# STM32WB30CEU6A register map
File version: 1.0
Registers are 32-bit, access not given, reset 0x0 unless marked. A register's access mark holds for its fields unless they carry their own. Offsets are from the block's base; [hi:lo] are bit positions; {n}, {i} and the like mark numbered series; 'fields as' and 'values as' point back to an identical list.

## RTCTAMP
Base 0x40002800
0x00 TR
  [22] PM, [21:20] HT, [19:16] HU, [14:12] MNT, [11:8] MNU, [31:7] s, [6:4] ST, [3:0] SU
0x04 DR
  [23:20] YT, [19:16] YU, [15:13] WDU, [12] MT, [11:8] MU, [31:6] s, [5:4] DT, [3:0] DU
0x08 CR
  [24] ITSE, [23] COE, [22:21] OSEL, [20] POL, [19] COSEL, [18] BKP, [17] SUB1H, [16] ADD1H, [15] TSIE, [14] WUTIE, [13] ALRBIE, [12] ALRAIE, [11] TSE, [10] WUTE, [9] ALRBE, [8] ALRAE, [31:7] s, [6] FMT, [5] BYPSHAD, [4] REFCKON, [3] TSEDGE, [2:0] WUCKSEL
0x0C ISR
  [17] ITSF, [16] RECALPF, [14] TAMP2F, [31:13] s, [12] TSOVF, [11] TSF, [10] WUTF, [9] ALRBF, [8] ALRAF, [7] INIT, [6] INITF, [5] RSF, [4] INITS, [3] SHPF, [2] WUTWF, [1] ALRBWF, [0] ALRAWF
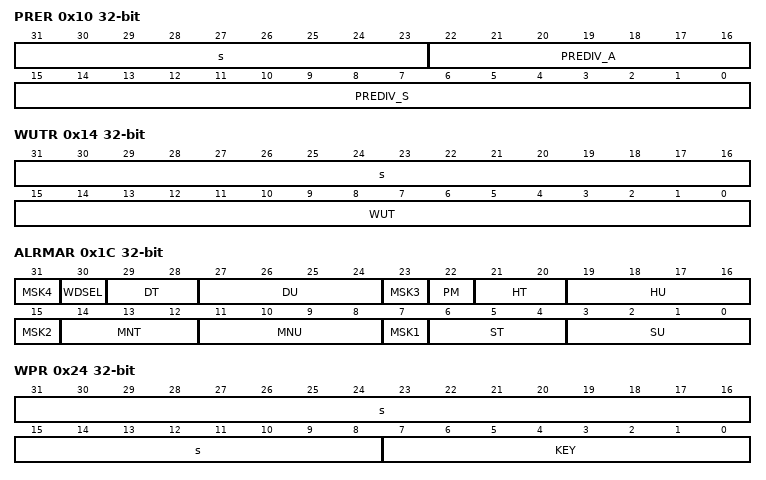
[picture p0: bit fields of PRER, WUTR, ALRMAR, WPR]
0x10 PRER
  [31:23] s, [22:16] PREDIV_A, [15:0] PREDIV_S
0x14 WUTR
  [31:16] s, [15:0] WUT
0x1C ALRMAR
  [8n-1] MSK{n} (n=1..4), [30] WDSEL, [29:28] DT, [27:24] DU, [22] PM, [21:20] HT, [19:16] HU, [14:12] MNT, [11:8] MNU, [6:4] ST, [3:0] SU
0x20 ALRMBR
  [31] MSK4, [30] WDSEL, [29:28] DT, [27:24] DU, [23] MSK3, [22] PM, [21:20] HT, [19:16] HU, [14:12] MNT, [11:8] MNU, [15:7] MSK2, [6:4] ST, [3:0] SU
0x24 WPR
  [31:8] s, [7:0] KEY
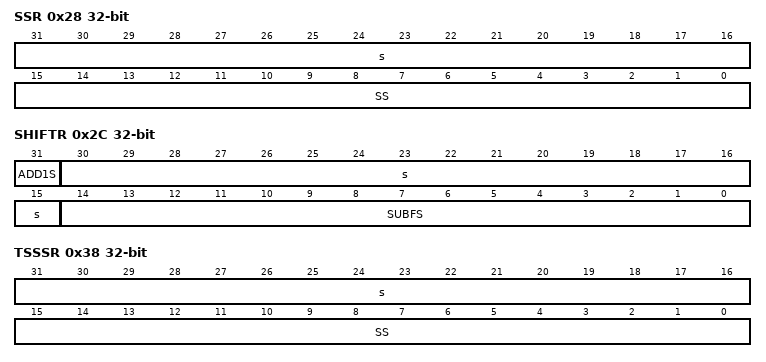
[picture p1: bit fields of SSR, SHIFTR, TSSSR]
0x28 SSR
  [31:16] s, [15:0] SS
0x2C SHIFTR
  [31] ADD1S, [30:15] s, [14:0] SUBFS
0x30 TSTR
  fields as TR
0x34 TSDR
  [15:13] WDU, [12] MT, [11:8] MU, [31:6] s, [5:4] DT, [3:0] DU
0x38 TSSSR
  [31:16] s, [15:0] SS
0x3C CALR
  [15] CALP, [14] CALW8, [13] CALW16, [31:9] s, [8:0] CALM
0x40 TAMPCR
  [21] TAMP2MF, [20] TAMP2NOERASE, [19] TAMP2IE, [15] TAMPPUDIS, [14:13] TAMPPRCH, [12:11] TAMPFLT, [10:8] TAMPFREQ, [7] TAMPTS, [4] TAMP2TRG, [3] TAMP2E, [2] TAMPIE, [31:0] s
0x44 ALRMASSR
  [27:24] MASKSS, [31:15] s, [14:0] SS
0x48 ALRMBSSR
  [27:24] MASKSS, [31:15] s, [14:0] SS
0x4C OR
  [1] RTC_OUT_RMP, [31:0] s
{0x50+4i} BKP{i}R (i=0..19)
  [31:0] BKP

## WWDG
Base 0x40002C00
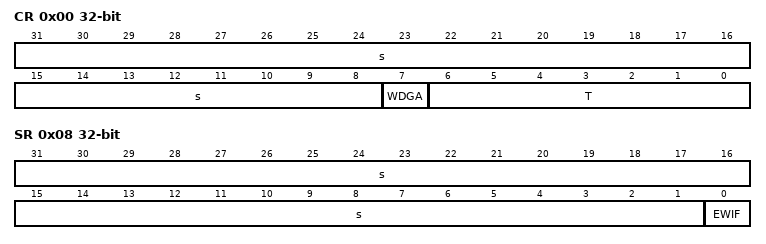
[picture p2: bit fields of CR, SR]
0x00 CR
  [31:8] s, [7] WDGA, [6:0] T
0x04 CFR
  [13:11] WDGTB, [9] EWI, [31:7] s, [6:0] W
0x08 SR
  [31:1] s, [0] EWIF

## IWDG
Base 0x40003000
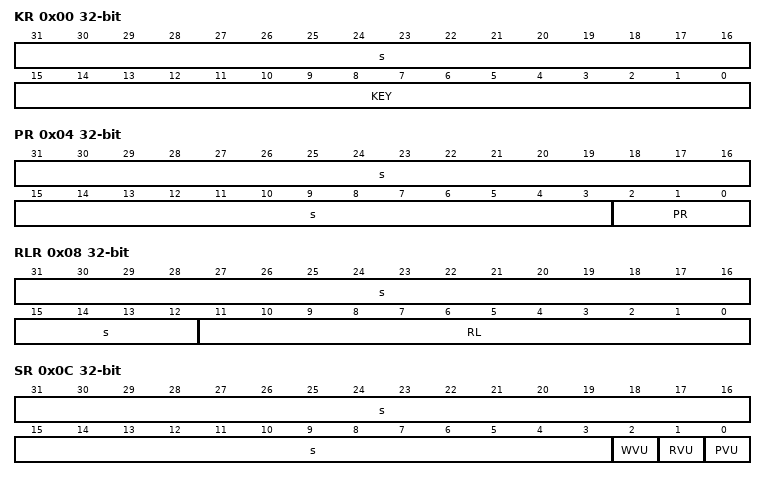
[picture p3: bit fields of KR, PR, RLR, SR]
0x00 KR
  [31:16] s, [15:0] KEY
0x04 PR
  [31:3] s, [2:0] PR
0x08 RLR
  [31:12] s, [11:0] RL
0x0C SR
  [31:3] s, [2] WVU, [1] RVU, [0] PVU
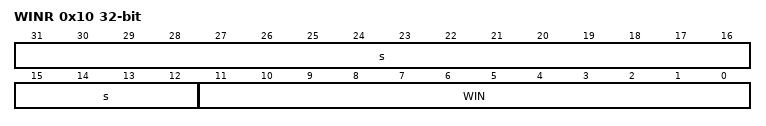
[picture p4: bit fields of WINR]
0x10 WINR
  [31:12] s, [11:0] WIN

## I2C1
Base 0x40005400
0x00 CR1
  [23] PECEN, [22] ALERTEN, [21] SMBDEN, [20] SMBHEN, [19] GCEN, [18] WUPEN, [17] NOSTRETCH, [16] SBC, [15] RXDMAEN, [14] TXDMAEN, [31:13] s, [12] ANFOFF, [11:8] DNF, [7] ERRIE, [6] TCIE, [5] STOPIE, [4] NACKIE, [3] ADDRIE, [2] RXIE, [1] TXIE, [0] PE
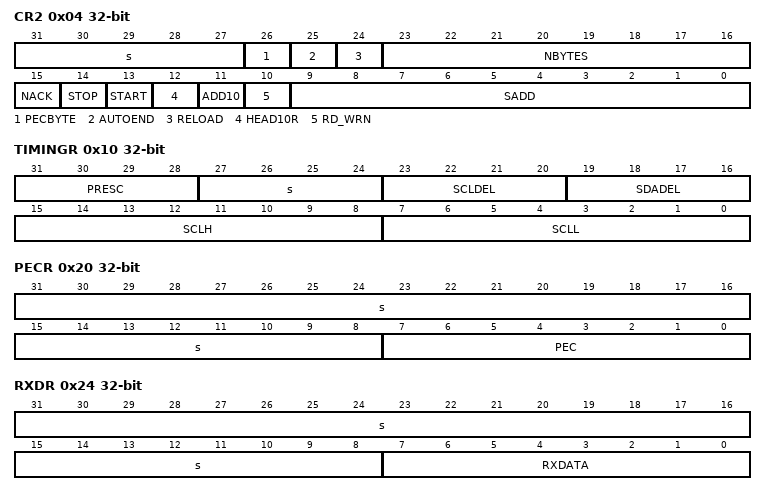
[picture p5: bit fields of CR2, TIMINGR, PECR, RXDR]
0x04 CR2
  [31:27] s, [26] PECBYTE, [25] AUTOEND, [24] RELOAD, [23:16] NBYTES, [15] NACK, [14] STOP, [13] START, [12] HEAD10R, [11] ADD10, [10] RD_WRN, [9:0] SADD
0x08 OAR1
  [15] OA1EN, [31:11] s, [10] OA1MODE, [9:0] OA1
0x0C OAR2
  [15] OA2EN, [10:8] OA2MSK, [7:1] OA2, [31:0] s
0x10 TIMINGR
  [31:28] PRESC, [27:24] s, [23:20] SCLDEL, [19:16] SDADEL, [15:8] SCLH, [7:0] SCLL
0x14 TIMEOUTR
  [31] TEXTEN, [27:16] TIMEOUTB, [15] TIMOUTEN, [30:13] s, [12] TIDLE, [11:0] TIMEOUTA
0x18 ISR
  [23:17] ADDCODE, [16] DIR, [15] BUSY, [31:14] s, [13] ALERT, [12] TIMEOUT, [11] PECERR, [10] OVR, [9] ARLO, [8] BERR, [7] TCR, [6] TC, [5] STOPF, [4] NACKF, [3] ADDR, [2] RXNE, [1] TXIS, [0] TXE
0x1C ICR
  [13] ALERTCF, [12] TIMOUTCF, [11] PECCF, [10] OVRCF, [9] ARLOCF, [8] BERRCF, [5] STOPCF, [4] NACKCF, [3] ADDRCF, [31:0] s
0x20 PECR
  [31:8] s, [7:0] PEC
0x24 RXDR
  [31:8] s, [7:0] RXDATA
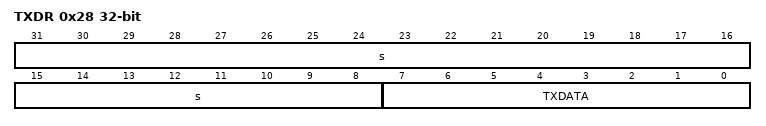
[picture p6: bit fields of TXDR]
0x28 TXDR
  [31:8] s, [7:0] TXDATA

## LPTIM1
Base 0x40007C00
0x00 CR1
  [11] UIFREMAP, [31:10] s, [9:8] CKD, [7] ARPE, [6:5] CMS, [4] DIR, [3] OPM, [2] URS, [1] UDIS, [0] CEN
0x04 CR2
  [23:20] MMS2, [2n+6] OIS{n} (n=1..6), [13] OIS3N, [11] OIS2N, [9] OIS1N, [7] TI1S, [6:4] MMS, [3] CCDS, [2] CCUS, [31:1] s, [0] CCPC
0x08 SMCR
  [31:17] s, [15] ETP, [14] ECE, [13:12] ETPS, [11:8] ETF, [7] MSM, [21:4] TS, [3] OCCS, [16:0] SMS
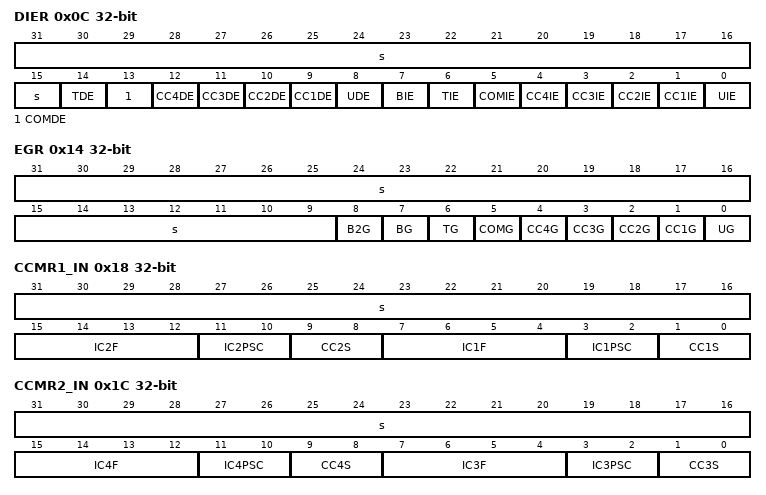
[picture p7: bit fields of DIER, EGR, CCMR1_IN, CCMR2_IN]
0x0C DIER
  [31:15] s, [14] TDE, [13] COMDE, [n+8] CC{n}DE (n=1..4), [8] UDE, [7] BIE, [6] TIE, [5] COMIE, [n] CC{n}IE (n=1..4), [0] UIE
0x10 SR
  [17] CC6IF, [16] CC5IF, [31:14] s, [13] SBIF, [n+8] CC{n}OF (n=1..4), [8] B2IF, [7] BIF, [6] TIF, [5] COMIF, [n] CC{n}IF (n=1..4), [0] UIF
0x14 EGR
  [31:9] s, [8] B2G, [7] BG, [6] TG, [5] COMG, [n] CC{n}G (n=1..4), [0] UG
0x18 CCMR1_OUT
  [31:17] s, [15] OC2CE, [24:12] OC2M, [11] OC2PE, [10] OC2FE, [9:8] CC2S, [7] OC1CE, [16:4] OC1M, [3] OC1PE, [2] OC1FE, [1:0] CC1S
0x18 CCMR1_IN
  [31:16] s, [15:12] IC2F, [11:10] IC2PSC, [9:8] CC2S, [7:4] IC1F, [3:2] IC1PSC, [1:0] CC1S
0x1C CCMR2_OUT
  [31:17] s, [15] OC4CE, [24:12] OC4M, [11] OC4PE, [10] OC4FE, [9:8] CC4S, [7] OC3CE, [16:4] OC3M, [3] OC3PE, [2] OC3FE, [1:0] CC3S
0x1C CCMR2_IN
  [31:16] s, [15:12] IC4F, [11:10] IC4PSC, [9:8] CC4S, [7:4] IC3F, [3:2] IC3PSC, [1:0] CC3S
0x20 CCER
  [4n-3] CC{n}P (n=1..6), [4n-4] CC{n}E (n=1..6), [4n-1] CC{n}NP (n=1..4), [31:14] s, [10] CC3NE, [6] CC2NE, [2] CC1NE
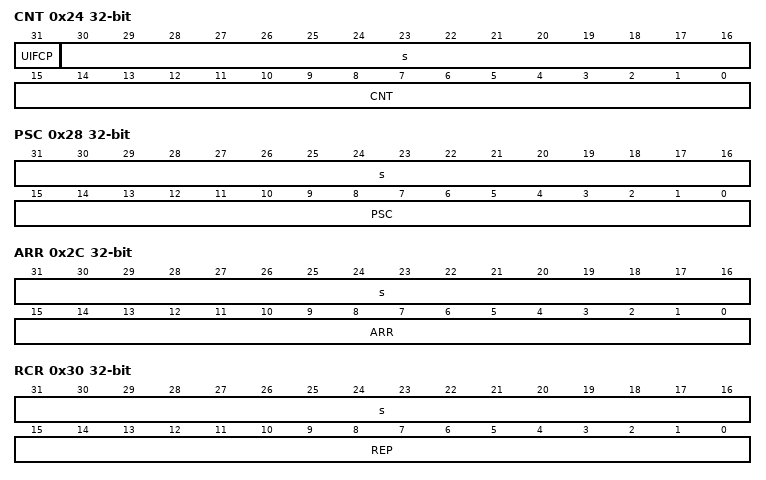
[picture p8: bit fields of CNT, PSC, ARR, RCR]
0x24 CNT
  [31] UIFCP, [30:16] s, [15:0] CNT
0x28 PSC
  [31:16] s, [15:0] PSC
0x2C ARR
  [31:16] s, [15:0] ARR
0x30 RCR
  [31:16] s, [15:0] REP
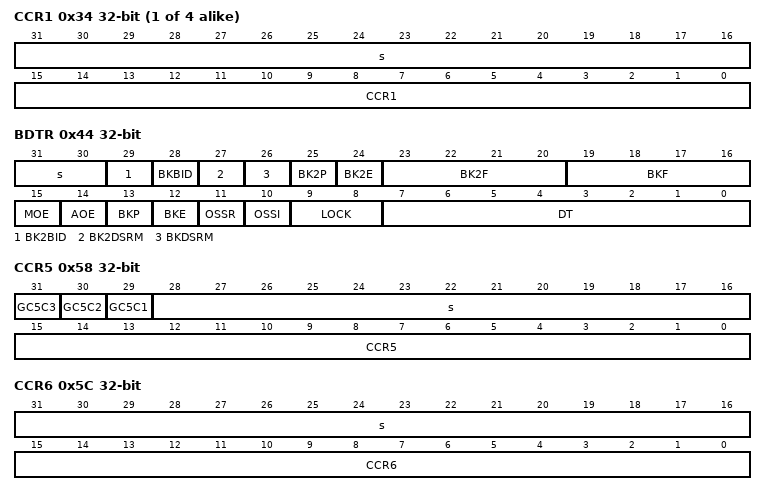
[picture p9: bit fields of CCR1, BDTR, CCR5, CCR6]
{0x30+4i} CCR{i} (i=1..4)
  [31:16] s, [15:0] CCR{i}
0x44 BDTR
  [31:30] s, [29] BK2BID, [28] BKBID, [27] BK2DSRM, [26] BKDSRM, [25] BK2P, [24] BK2E, [23:20] BK2F, [19:16] BKF, [15] MOE, [14] AOE, [13] BKP, [12] BKE, [11] OSSR, [10] OSSI, [9:8] LOCK, [7:0] DT
0x48 DCR
  [12:8] DBL, [31:5] s, [4:0] DBA
0x4C DMAR
  [31:0] DMAB
0x50 OR1
  [4] TI1_RMP, [31:2] s, [1:0] TIM1_ETR_ADC_RMP
0x54 CCMR3_OUT
  [15] OC6CE, [24:12] OC6M, [11] OC6PE, [10] OC6FE, [7] OC5CE, [16:4] OC5M, [3] OC5PE, [2] OC5FE, [31:0] s
0x58 CCR5
  [31] GC5C3, [30] GC5C2, [29] GC5C1, [28:16] s, [15:0] CCR5
0x5C CCR6
  [31:16] s, [15:0] CCR6
0x60 AF1
  [17:14] sETRSEL, [9] BKINP, [31:1] s, [0] BKINE
0x64 AF2
  [9] BK2INP, [31:1] s, [0] BK2INE
0x68 TISEL
  [8n-5:8n-8] TI{n}SEL (n=1..4), [31:4] s

## TIM1
Base 0x40012C00
Registers as LPTIM1; these are added or differ:
0x50 OR1
  [4] TI1_RMP, [31:2] s, [1:0] TIM1_ETR_ADC_RMP
